# STM32L162 register map
File version: 1.5
CPU: CM3 r1p1, little endian, no MPU, no FPU, 4 interrupt priority bits
Registers are 32-bit, read-write, reset 0x0 unless marked. A register's access mark holds for its fields unless they carry their own. Offsets are from the block's base; [hi:lo] are bit positions; lines under a group give offsets from that group; {n}, {i} and the like mark numbered series.

## ADC — Analog-to-digital converter
Base 0x40012400
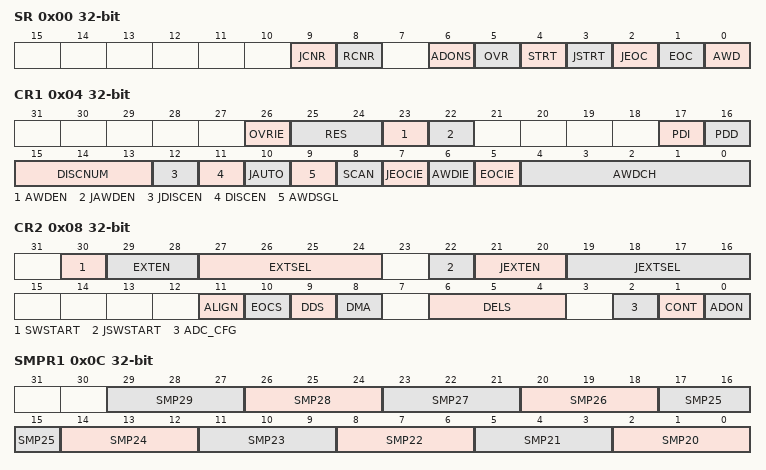
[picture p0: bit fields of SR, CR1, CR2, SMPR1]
0x00 SR access per field — status register
  [9] JCNR ro — Injected channel not ready
  [8] RCNR ro — Regular channel not ready
  [6] ADONS ro — ADC ON status
  [5] OVR rw — Overrun
  [4] STRT rw — Regular channel start flag
  [3] JSTRT rw — Injected channel start flag
  [2] JEOC rw — Injected channel end of conversion
  [1] EOC rw — Regular channel end of conversion
  [0] AWD rw — Analog watchdog flag
0x04 CR1 — control register 1
  [26] OVRIE — Overrun interrupt enable
  [25:24] RES — Resolution
  [23] AWDEN — Analog watchdog enable on regular channels
  [22] JAWDEN — Analog watchdog enable on injected channels
  [17] PDI — Power down during the idle phase
  [16] PDD — Power down during the delay phase
  [15:13] DISCNUM — Discontinuous mode channel count
  [12] JDISCEN — Discontinuous mode on injected channels
  [11] DISCEN — Discontinuous mode on regular channels
  [10] JAUTO — Automatic injected group conversion
  [9] AWDSGL — Enable the watchdog on a single channel in scan mode
  [8] SCAN — Scan mode
  [7] JEOCIE — Interrupt enable for injected channels
  [6] AWDIE — Analog watchdog interrupt enable
  [5] EOCIE — Interrupt enable for EOC
  [4:0] AWDCH — Analog watchdog channel select bits
0x08 CR2 — control register 2
  [30] SWSTART — Start conversion of regular channels
  [29:28] EXTEN — External trigger enable for regular channels
  [27:24] EXTSEL — External event select for regular group
  [22] JSWSTART — Start conversion of injected channels
  [21:20] JEXTEN — External trigger enable for injected channels
  [19:16] JEXTSEL — External event select for injected group
  [11] ALIGN — Data alignment
  [10] EOCS — End of conversion selection
  [9] DDS — DMA disable selection
  [8] DMA — Direct memory access mode
  [6:4] DELS — Delay selection
  [2] ADC_CFG — ADC configuration
  [1] CONT — Continuous conversion
  [0] ADON — A/D Converter ON / OFF
0x0C SMPR1 — sample time register 1
  [3n-58:3n-60] SMP{n} (n=20..29) — Channel {n} sample time selection
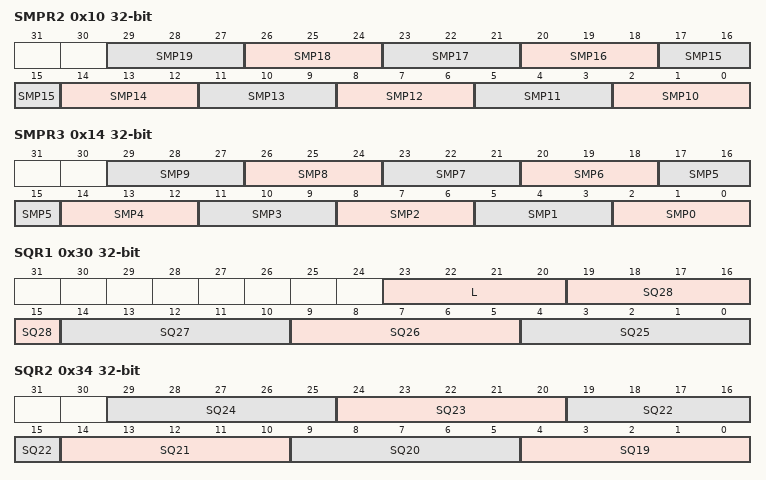
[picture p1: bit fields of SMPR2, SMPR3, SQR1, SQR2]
0x10 SMPR2 — sample time register 2
  [3n-28:3n-30] SMP{n} (n=10..19) — Channel {n} sample time selection
0x14 SMPR3 — sample time register 3
  [3n+2:3n] SMP{n} (n=0..9) — Channel {n} sample time selection
{0x14+4i} JOFR{i} (i=1..4) — injected channel data offset register {i}
  [11:0] JOFFSET — Data offset for injected channel
0x28 HTR reset 0xFFF — watchdog higher threshold register
  [11:0] HT — Analog watchdog higher threshold
0x2C LTR — watchdog lower threshold register
  [11:0] LT — Analog watchdog lower threshold
0x30 SQR1 — regular sequence register 1
  [23:20] L — Regular channel sequence length
  [5n-121:5n-125] SQ{n} (n=25..28) — {n} conversion in regular sequence
0x34 SQR2 — regular sequence register 2
  [5n-91:5n-95] SQ{n} (n=19..24) — {n} conversion in regular sequence
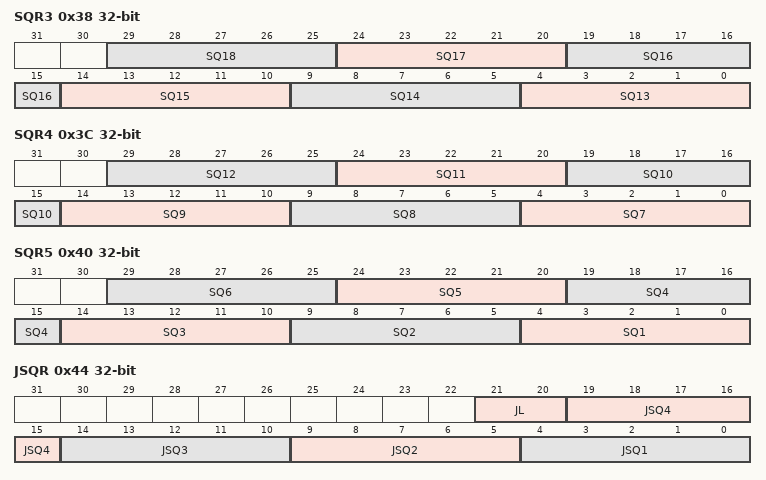
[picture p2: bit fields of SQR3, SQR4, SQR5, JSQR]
0x38 SQR3 — regular sequence register 3
  [5n-61:5n-65] SQ{n} (n=13..18) — {n} conversion in regular sequence
0x3C SQR4 — regular sequence register 4
  [5n-31:5n-35] SQ{n} (n=7..12) — {n} conversion in regular sequence
0x40 SQR5 — regular sequence register 5
  [5n-1:5n-5] SQ{n} (n=1..6) — {n} conversion in regular sequence
0x44 JSQR — injected sequence register
  [21:20] JL — Injected sequence length
  [5n-1:5n-5] JSQ{n} (n=1..4) — {n} conversion in injected sequence
{0x44+4i} JDR{i} (i=1..4) ro — injected data register x
  [15:0] JDATA — Injected data
0x58 DR ro — regular data register
  [15:0] RegularDATA
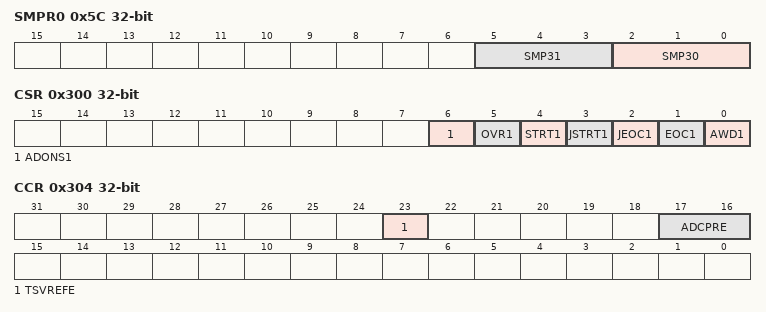
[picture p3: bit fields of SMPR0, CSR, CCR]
0x5C SMPR0 — sample time register 0
  [3n-88:3n-90] SMP{n} (n=30..31) — Channel {n} sample time selection
0x300 CSR ro — ADC common status register
  [6] ADONS1 — ADON Status of ADC1
  [5] OVR1 — Overrun flag of the ADC
  [4] STRT1 — Regular channel Start flag of the ADC
  [3] JSTRT1 — Injected channel Start flag of the ADC
  [2] JEOC1 — Injected channel end of conversion of the ADC
  [1] EOC1 — End of conversion of the ADC
  [0] AWD1 — Analog watchdog flag of the ADC
0x304 CCR — ADC common control register
  [23] TSVREFE — Temperature sensor and VREFINT enable
  [17:16] ADCPRE — ADC prescaler
